# SMS_WDTCTRL_1_SMS_HSM_CTRL_MMR_43936000h register map
Vendor: Texas Instruments
Peripheral module from a debugger description file (folder AM275x).
Registers are 32-bit, read-write, reset 0x0 unless marked. A register's access mark holds for its fields unless they carry their own. Offsets are as the file gives them; lines under a group give offsets from that group; [hi:lo] are bit positions; {n}, {i} and the like mark numbered series; 'fields as' and 'values as' point back to an identical list; <NAME> marks a mode.

## SMS_hsm_ctrl_mmr
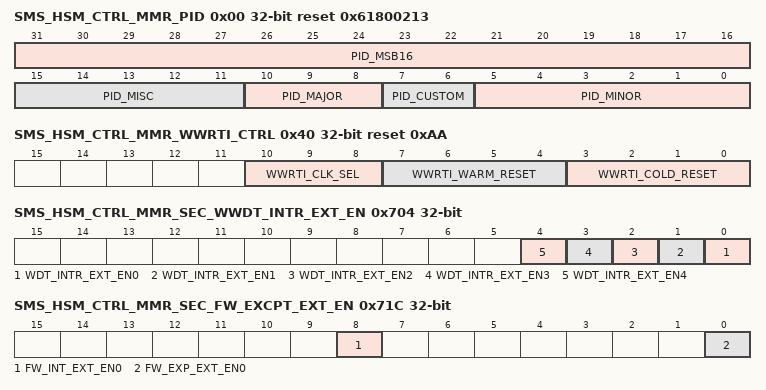
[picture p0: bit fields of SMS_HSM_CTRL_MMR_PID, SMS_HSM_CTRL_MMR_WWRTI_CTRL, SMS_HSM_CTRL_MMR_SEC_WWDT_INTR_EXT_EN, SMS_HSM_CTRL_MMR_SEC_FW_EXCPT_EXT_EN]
0x00 SMS_HSM_CTRL_MMR_PID ro reset 0x61800213
  [31:16] PID_MSB16 — Reset Source: mod_g_rst_n
  [15:11] PID_MISC — Reset Source: mod_g_rst_n
  [10:8] PID_MAJOR — Reset Source: mod_g_rst_n
  [7:6] PID_CUSTOM — Reset Source: mod_g_rst_n
  [5:0] PID_MINOR — Reset Source: mod_g_rst_n
0x20 SMS_HSM_CTRL_MMR_LOCK0_KICK0
  [31:0] LOCK0_KICK0 — - KICK0 component Reset Source: mod_g_rst_n
0x24 SMS_HSM_CTRL_MMR_LOCK0_KICK1
  [31:0] LOCK0_KICK1 — - KICK1 component Reset Source: mod_g_rst_n
0x40 SMS_HSM_CTRL_MMR_WWRTI_CTRL reset 0xAA
  [10:8] WWRTI_CLK_SEL — Reset Source: mod_por_rst_n
  [7:4] WWRTI_WARM_RESET — Reset Source: mod_por_rst_n
  [3:0] WWRTI_COLD_RESET — Reset Source: mod_por_rst_n
0x50 SMS_HSM_CTRL_MMR_WWRTI_CLOCK_CTRL reset 0xA
  [3:0] WWRTI_CLK_CTRL — Reset Source: mod_por_rst_n
0x704 SMS_HSM_CTRL_MMR_SEC_WWDT_INTR_EXT_EN
  [n] WDT_INTR_EXT_EN{n} (n=0..4) — Reset Source: mod_por_rst_n
0x70C SMS_HSM_CTRL_MMR_SEC_ECC_AGGR_INTR_EXT_EN
  [0] ECC_AGGR_INTR_EXT_EN0 — Reset Source: mod_por_rst_n
0x71C SMS_HSM_CTRL_MMR_SEC_FW_EXCPT_EXT_EN
  [8] FW_INT_EXT_EN0 — Reset Source: mod_por_rst_n
  [0] FW_EXP_EXT_EN0 — Reset Source: mod_por_rst_n
0x724 SMS_HSM_CTRL_MMR_SEC_RAT_INTR_EXT_EN
  [0] RAT_INTR_EXT_EN — Reset Source: mod_por_rst_n
0x800 SMS_HSM_CTRL_MMR_SEC_HSM_RESET
  [1] RESET_MASK — Reset Source: mod_por_rst_n
